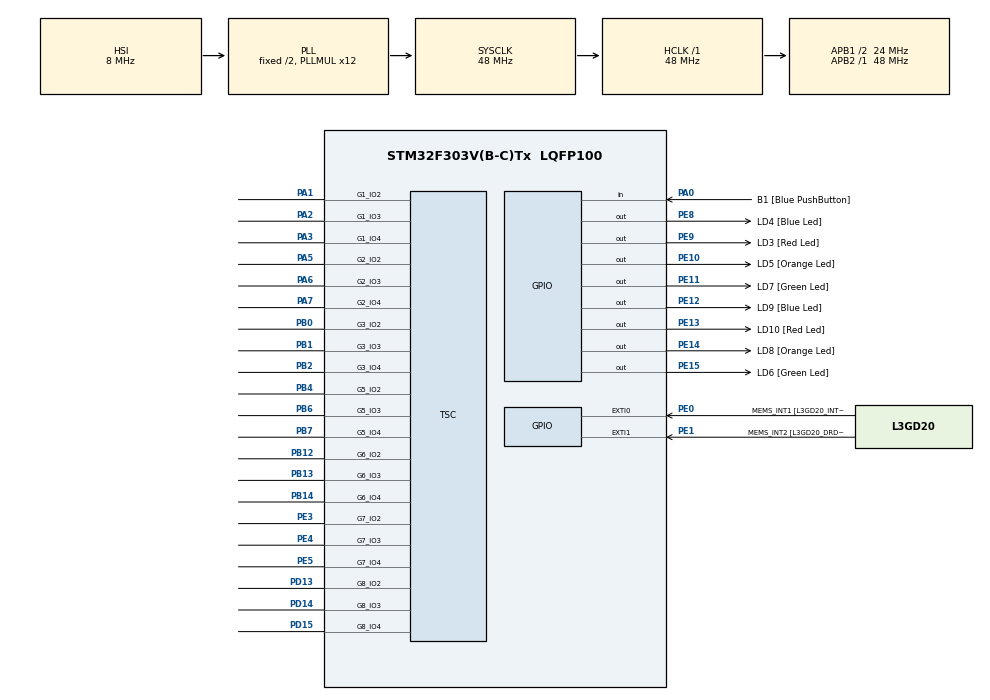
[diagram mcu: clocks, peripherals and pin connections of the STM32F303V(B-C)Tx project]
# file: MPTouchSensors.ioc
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Mcu.Family=STM32F3
Mcu.Name=STM32F303V(B-C)Tx
Mcu.Package=LQFP100
NVIC.PriorityGroup=NVIC_PRIORITYGROUP_0
PA0.GPIO_Label=B1 [Blue PushButton]
PA0.GPIO_Mode=GPIO_MODE_INPUT
PA0.GPIO_PuPd=GPIO_NOPULL
PA0.Signal=GPIO_Input
PA1.Mode=G1_IO2-Channel
PA1.Signal=TSC_G1_IO2
PA11.GPIO_Label=DM
PA11.Signal=USB_DM
PA12.GPIO_Label=DP
PA12.Signal=USB_DP
PA13.Signal=SYS_JTMS-SWDIO
PA14.GPIO_Label=SWCLK
PA14.Signal=SYS_JTCK-SWCLK
PA15.Signal=S_TIM2_CH1_ETR
PA2.Mode=G1_IO3-Sampling
PA2.Signal=TSC_G1_IO3
PA3.Mode=G1_IO4-Channel
PA3.Signal=TSC_G1_IO4
PA5.Mode=G2_IO2-Channel
PA5.Signal=TSC_G2_IO2
PA6.Mode=G2_IO3-Sampling
PA6.Signal=TSC_G2_IO3
PA7.Mode=G2_IO4-Channel
PA7.Signal=TSC_G2_IO4
PB0.Mode=G3_IO2-Channel
PB0.Signal=TSC_G3_IO2
PB1.Mode=G3_IO3-Sampling
PB1.Signal=TSC_G3_IO3
PB12.Mode=G6_IO2-Channel
PB12.Signal=TSC_G6_IO2
PB13.Mode=G6_IO3-Sampling
PB13.Signal=TSC_G6_IO3
PB14.Mode=G6_IO4-Channel
PB14.Signal=TSC_G6_IO4
PB2.Mode=G3_IO4-Channel
PB2.Signal=TSC_G3_IO4
PB3.GPIO_Label=SWO
PB3.Signal=SYS_JTDO-TRACESWO
PB4.Mode=G5_IO2-Channel
PB4.Signal=TSC_G5_IO2
PB6.Mode=G5_IO3-Sampling
PB6.Signal=TSC_G5_IO3
PB7.Mode=G5_IO4-Channel
PB7.Signal=TSC_G5_IO4
PC14-OSC32_IN.GPIO_Label=OSC32_IN
PC14-OSC32_IN.Signal=RCC_OSC32_IN
PC15-OSC32_OUT.GPIO_Label=OSC32_OUT
PC15-OSC32_OUT.Signal=RCC_OSC32_OUT
PD13.Mode=G8_IO2-Channel
PD13.Signal=TSC_G8_IO2
PD14.Mode=G8_IO3-Sampling
PD14.Signal=TSC_G8_IO3
PD15.Mode=G8_IO4-Channel
PD15.Signal=TSC_G8_IO4
PE0.GPIO_Label=MEMS_INT1 [L3GD20_INT1]
PE0.GPIO_ModeDefaultEXTI=GPIO_MODE_EVT_RISING
PE0.GPIO_PuPd=GPIO_NOPULL
PE0.Signal=GPXTI0
PE1.GPIO_Label=MEMS_INT2 [L3GD20_DRDY/INT2]
PE1.GPIO_ModeDefaultEXTI=GPIO_MODE_EVT_RISING
PE1.GPIO_PuPd=GPIO_NOPULL
PE1.Signal=GPXTI1
PE10.GPIO_Label=LD5 [Orange Led]
PE10.GPIO_ModeDefaultOutputPP=GPIO_MODE_OUTPUT_PP
PE10.GPIO_PuPd=GPIO_NOPULL
PE10.GPIO_Speed=GPIO_SPEED_FREQ_LOW
PE10.Signal=GPIO_Output
PE11.GPIO_Label=LD7 [Green Led]
PE11.GPIO_ModeDefaultOutputPP=GPIO_MODE_OUTPUT_PP
PE11.GPIO_PuPd=GPIO_NOPULL
PE11.GPIO_Speed=GPIO_SPEED_FREQ_LOW
PE11.Signal=GPIO_Output
PE12.GPIO_Label=LD9 [Blue Led]
PE12.GPIO_ModeDefaultOutputPP=GPIO_MODE_OUTPUT_PP
PE12.GPIO_PuPd=GPIO_NOPULL
PE12.GPIO_Speed=GPIO_SPEED_FREQ_LOW
PE12.Signal=GPIO_Output
PE13.GPIO_Label=LD10 [Red Led]
PE13.GPIO_ModeDefaultOutputPP=GPIO_MODE_OUTPUT_PP
PE13.GPIO_PuPd=GPIO_NOPULL
PE13.GPIO_Speed=GPIO_SPEED_FREQ_LOW
PE13.Signal=GPIO_Output
PE14.GPIO_Label=LD8 [Orange Led]
PE14.GPIO_ModeDefaultOutputPP=GPIO_MODE_OUTPUT_PP
PE14.GPIO_PuPd=GPIO_NOPULL
PE14.GPIO_Speed=GPIO_SPEED_FREQ_LOW
PE14.Signal=GPIO_Output
PE15.GPIO_Label=LD6 [Green Led]
PE15.GPIO_ModeDefaultOutputPP=GPIO_MODE_OUTPUT_PP
PE15.GPIO_PuPd=GPIO_NOPULL
PE15.GPIO_Speed=GPIO_SPEED_FREQ_LOW
PE15.Signal=GPIO_Output
PE3.Mode=G7_IO2-Channel
PE3.Signal=TSC_G7_IO2
PE4.Mode=G7_IO3-Sampling
PE4.Signal=TSC_G7_IO3
PE5.Mode=G7_IO4-Channel
PE5.Signal=TSC_G7_IO4
PE8.GPIO_Label=LD4 [Blue Led]
PE8.GPIO_ModeDefaultOutputPP=GPIO_MODE_OUTPUT_PP
PE8.GPIO_PuPd=GPIO_NOPULL
PE8.GPIO_Speed=GPIO_SPEED_FREQ_LOW
PE8.Signal=GPIO_Output
PE9.GPIO_Label=LD3 [Red Led]
PE9.GPIO_ModeDefaultOutputPP=GPIO_MODE_OUTPUT_PP
PE9.GPIO_PuPd=GPIO_NOPULL
PE9.GPIO_Speed=GPIO_SPEED_FREQ_LOW
PE9.Signal=GPIO_Output
PF0-OSC_IN.GPIO_Label=OSC_IN
PF0-OSC_IN.Signal=RCC_OSC_IN
PF1-OSC_OUT.GPIO_Label=OSC_OUT
PF1-OSC_OUT.Signal=RCC_OSC_OUT
ProjectManager.HeapSize=0x200
ProjectManager.StackSize=0x400
ProjectManager.TargetToolchain=STM32CubeIDE
RCC.AHBFreq_Value=48000000
RCC.APB1CLKDivider=RCC_HCLK_DIV2
RCC.APB1Freq_Value=24000000
RCC.APB1TimFreq_Value=48000000
RCC.APB2Freq_Value=48000000
RCC.APB2TimFreq_Value=48000000
RCC.CortexFreq_Value=48000000
RCC.HCLKFreq_Value=48000000
RCC.HSE_VALUE=8000000
RCC.HSI_VALUE=8000000
RCC.LSE_VALUE=32768
RCC.PLLMUL=RCC_PLL_MUL12
RCC.SYSCLKFreq_VALUE=48000000
RCC.SYSCLKSourceVirtual=RCC_SYSCLKSOURCE_PLLCLK
RCC.USBFreq_Value=48000000
SH.S_TIM2_CH1_ETR.0=TIM2_CH1
TSC.ChannelIOs-G1_IO2-Channel=TSC_GROUP1_IO2
TSC.ChannelIOs-G1_IO4-Channel=TSC_GROUP1_IO4
TSC.ChannelIOs-G2_IO2-Channel=TSC_GROUP2_IO2
TSC.ChannelIOs-G2_IO4-Channel=TSC_GROUP2_IO4
TSC.ChannelIOs-G3_IO2-Channel=TSC_GROUP3_IO2
TSC.ChannelIOs-G3_IO4-Channel=TSC_GROUP3_IO4
TSC.ChannelIOs-G5_IO2-Channel=TSC_GROUP5_IO2
TSC.ChannelIOs-G5_IO4-Channel=TSC_GROUP5_IO4
TSC.ChannelIOs-G6_IO2-Channel=TSC_GROUP6_IO2
TSC.ChannelIOs-G6_IO4-Channel=TSC_GROUP6_IO4
TSC.ChannelIOs-G7_IO2-Channel=TSC_GROUP7_IO2
TSC.ChannelIOs-G7_IO4-Channel=TSC_GROUP7_IO4
TSC.ChannelIOs-G8_IO2-Channel=TSC_GROUP8_IO2
TSC.ChannelIOs-G8_IO4-Channel=TSC_GROUP8_IO4
TSC.SamplingIOs-G1_IO3-Sampling=TSC_GROUP1_IO3
TSC.SamplingIOs-G2_IO3-Sampling=TSC_GROUP2_IO3
TSC.SamplingIOs-G3_IO3-Sampling=TSC_GROUP3_IO3
TSC.SamplingIOs-G5_IO3-Sampling=TSC_GROUP5_IO3
TSC.SamplingIOs-G6_IO3-Sampling=TSC_GROUP6_IO3
TSC.SamplingIOs-G7_IO3-Sampling=TSC_GROUP7_IO3
TSC.SamplingIOs-G8_IO3-Sampling=TSC_GROUP8_IO3
board=STM32F3DISCOVERY

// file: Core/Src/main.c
/* USER CODE BEGIN Header */
/**
  ******************************************************************************
  * @file           : main.c
  * @brief          : Main program body
  ******************************************************************************
  * @attention
  *
  * Copyright (c) 2025 STMicroelectronics.
  * All rights reserved.
  *
  * This software is licensed under terms that can be found in the LICENSE file
  * in the root directory of this software component.
  * If no LICENSE file comes with this software, it is provided AS-IS.
  *
  ******************************************************************************
  */
/* USER CODE END Header */
#include "main.h"
#include <stdio.h>
#include <string.h>
#include "serial.h"
#include "stm32f3xx_hal.h"
#include "game.h"
#include "led_control.h"
#include "uart4.h"

TSC_HandleTypeDef htsc;

/* USER CODE BEGIN PV */
uint32_t tsc_value;
char uart_msg[64];
/* USER CODE END PV */

void SystemClock_Config(void);
static void MX_GPIO_Init(void);
static void MX_TSC_Init(void);

int main(void)
{
	    HAL_Init();
	    SystemClock_Config();
	    MX_GPIO_Init();
	    MX_TSC_Init();
	    UART4_Init();

	    // Initialise UART on USART1 at 115200 baud
	    SerialInitialise(BAUD_115200, &USART1_PORT, NULL);

	    while (1)
	    {
	    UART4_SendByte('1');
	    }

	    // Wait until UART4 receives the '1' byte
	    uint8_t received = 0;
	    do {
	        received = UART4_ReceiveByte();
	    } while (received != '1');

	    StartMinigame(&htsc);

	    // Optional: stay in infinite loop after game ends
	    while (1)
	    {
	    }
}

void SystemClock_Config(void)
{
  RCC_OscInitTypeDef RCC_OscInitStruct = {0};
  RCC_ClkInitTypeDef RCC_ClkInitStruct = {0};

  /** Initializes the RCC Oscillators according to the specified parameters
  * in the RCC_OscInitTypeDef structure.
  */
  RCC_OscInitStruct.OscillatorType = RCC_OSCILLATORTYPE_HSI;
  RCC_OscInitStruct.HSIState = RCC_HSI_ON;
  RCC_OscInitStruct.HSICalibrationValue = RCC_HSICALIBRATION_DEFAULT;
  RCC_OscInitStruct.PLL.PLLState = RCC_PLL_ON;
  RCC_OscInitStruct.PLL.PLLSource = RCC_PLLSOURCE_HSI;
  RCC_OscInitStruct.PLL.PLLMUL = RCC_PLL_MUL12;
  if (HAL_RCC_OscConfig(&RCC_OscInitStruct) != HAL_OK)
  {
    Error_Handler();
  }

  /** Initializes the CPU, AHB and APB buses clocks
  */
  RCC_ClkInitStruct.ClockType = RCC_CLOCKTYPE_HCLK|RCC_CLOCKTYPE_SYSCLK
                              |RCC_CLOCKTYPE_PCLK1|RCC_CLOCKTYPE_PCLK2;
  RCC_ClkInitStruct.SYSCLKSource = RCC_SYSCLKSOURCE_PLLCLK;
  RCC_ClkInitStruct.AHBCLKDivider = RCC_SYSCLK_DIV1;
  RCC_ClkInitStruct.APB1CLKDivider = RCC_HCLK_DIV2;
  RCC_ClkInitStruct.APB2CLKDivider = RCC_HCLK_DIV1;

  if (HAL_RCC_ClockConfig(&RCC_ClkInitStruct, FLASH_LATENCY_1) != HAL_OK)
  {
    Error_Handler();
  }
}

static void MX_TSC_Init(void)
{

  /** Configure the TSC peripheral
  */
  htsc.Instance = TSC;
  htsc.Init.CTPulseHighLength = TSC_CTPH_2CYCLES;
  htsc.Init.CTPulseLowLength = TSC_CTPL_2CYCLES;
  htsc.Init.SpreadSpectrum = DISABLE;
  htsc.Init.SpreadSpectrumDeviation = 1;
  htsc.Init.SpreadSpectrumPrescaler = TSC_SS_PRESC_DIV1;
  htsc.Init.PulseGeneratorPrescaler = TSC_PG_PRESC_DIV4;
  htsc.Init.MaxCountValue = TSC_MCV_8191;
  htsc.Init.IODefaultMode = TSC_IODEF_OUT_PP_LOW;
  htsc.Init.SynchroPinPolarity = TSC_SYNC_POLARITY_FALLING;
  htsc.Init.AcquisitionMode = TSC_ACQ_MODE_NORMAL;
  htsc.Init.MaxCountInterrupt = DISABLE;
  htsc.Init.ChannelIOs = TSC_GROUP1_IO2|TSC_GROUP1_IO4|TSC_GROUP2_IO2|TSC_GROUP2_IO4
                    |TSC_GROUP3_IO2|TSC_GROUP3_IO4|TSC_GROUP5_IO2|TSC_GROUP5_IO4
                    |TSC_GROUP6_IO2|TSC_GROUP6_IO4|TSC_GROUP7_IO2|TSC_GROUP7_IO4
                    |TSC_GROUP8_IO2|TSC_GROUP8_IO4;
  htsc.Init.ShieldIOs = 0;
  htsc.Init.SamplingIOs = TSC_GROUP1_IO3|TSC_GROUP2_IO3|TSC_GROUP3_IO3|TSC_GROUP5_IO3
                    |TSC_GROUP6_IO3|TSC_GROUP7_IO3|TSC_GROUP8_IO3;
  if (HAL_TSC_Init(&htsc) != HAL_OK)
  {
    Error_Handler();
  }

}

static void MX_GPIO_Init(void)
{
  GPIO_InitTypeDef GPIO_InitStruct = {0};

  /* GPIO Ports Clock Enable */
  __HAL_RCC_GPIOE_CLK_ENABLE();
  __HAL_RCC_GPIOC_CLK_ENABLE();
  __HAL_RCC_GPIOF_CLK_ENABLE();
  __HAL_RCC_GPIOA_CLK_ENABLE();
  __HAL_RCC_GPIOB_CLK_ENABLE();
  __HAL_RCC_GPIOD_CLK_ENABLE();

  /*Configure GPIO pin Output Level */
  HAL_GPIO_WritePin(GPIOE, LD4_Pin|LD3_Pin|LD5_Pin|LD7_Pin
                          |LD9_Pin|LD10_Pin|LD8_Pin|LD6_Pin, GPIO_PIN_RESET);

  /*Configure GPIO pin : B1_Pin */
  GPIO_InitStruct.Pin = B1_Pin;
  GPIO_InitStruct.Mode = GPIO_MODE_INPUT;
  GPIO_InitStruct.Pull = GPIO_NOPULL;
  HAL_GPIO_Init(B1_GPIO_Port, &GPIO_InitStruct);

  /*Configure GPIO pins : LD4_Pin LD3_Pin LD5_Pin LD7_Pin
                           LD9_Pin LD10_Pin LD8_Pin LD6_Pin */
  GPIO_InitStruct.Pin = LD4_Pin|LD3_Pin|LD5_Pin|LD7_Pin
                          |LD9_Pin|LD10_Pin|LD8_Pin|LD6_Pin;
  GPIO_InitStruct.Mode = GPIO_MODE_OUTPUT_PP;
  GPIO_InitStruct.Pull = GPIO_NOPULL;
  GPIO_InitStruct.Speed = GPIO_SPEED_FREQ_LOW;
  HAL_GPIO_Init(GPIOE, &GPIO_InitStruct);

  /*Configure GPIO pins : DM_Pin DP_Pin */
  GPIO_InitStruct.Pin = DM_Pin|DP_Pin;
  GPIO_InitStruct.Mode = GPIO_MODE_AF_PP;
  GPIO_InitStruct.Pull = GPIO_NOPULL;
  GPIO_InitStruct.Speed = GPIO_SPEED_FREQ_HIGH;
  GPIO_InitStruct.Alternate = GPIO_AF14_USB;
  HAL_GPIO_Init(GPIOA, &GPIO_InitStruct);

  /*Configure GPIO pin : PA15 */
  GPIO_InitStruct.Pin = GPIO_PIN_15;
  GPIO_InitStruct.Mode = GPIO_MODE_AF_PP;
  GPIO_InitStruct.Pull = GPIO_NOPULL;
  GPIO_InitStruct.Speed = GPIO_SPEED_FREQ_LOW;
  GPIO_InitStruct.Alternate = GPIO_AF1_TIM2;
  HAL_GPIO_Init(GPIOA, &GPIO_InitStruct);

  /*Configure GPIO pins : MEMS_INT1_Pin MEMS_INT2_Pin */
  GPIO_InitStruct.Pin = MEMS_INT1_Pin|MEMS_INT2_Pin;
  GPIO_InitStruct.Mode = GPIO_MODE_EVT_RISING;
  GPIO_InitStruct.Pull = GPIO_NOPULL;
  HAL_GPIO_Init(GPIOE, &GPIO_InitStruct);

}

void Error_Handler(void)
{
  __disable_irq();
  while (1)
  {
  }
}
